# SPI6 register map
Registers from a debugger description file.
Registers are 32-bit, access not given, no defined reset value unless marked. A register's access mark holds for its fields unless they carry their own. Addresses are absolute; registers are grouped by the start of their names; lines under a group give offsets from that group; [hi:lo] are bit positions; {n}, {i} and the like mark numbered series; 'fields as' and 'values as' point back to an identical list; <NAME> marks a mode.

## SPI6
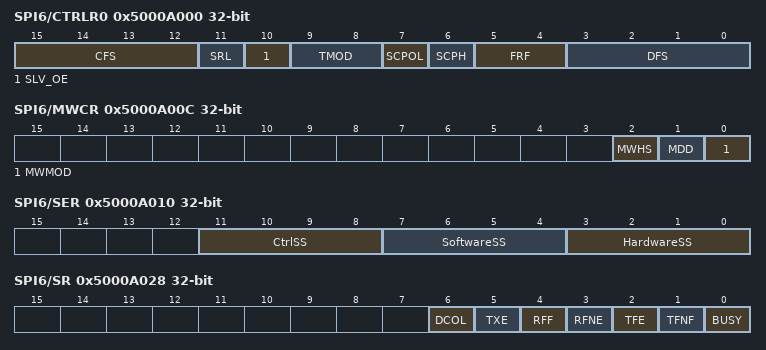
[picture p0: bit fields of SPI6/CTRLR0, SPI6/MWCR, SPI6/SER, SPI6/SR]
0x5000A000 SPI6/CTRLR0
  [15:12] CFS, [11] SRL, [10] SLV_OE, [9:8] TMOD, [7] SCPOL, [6] SCPH, [5:4] FRF, [3:0] DFS
0x5000A004 SPI6/CTRLR1
  [15:0] NDF
0x5000A008 SPI6/SSIENR
  [0] SSIENR
0x5000A00C SPI6/MWCR
  [2] MWHS, [1] MDD, [0] MWMOD
0x5000A010 SPI6/SER
  [11:8] CtrlSS, [7:4] SoftwareSS, [3:0] HardwareSS
0x5000A014 SPI6/BAUDR
  [15:0] SCKDV
0x5000A018 SPI6/TXFTLR
  [3:0] TFT
0x5000A01C SPI6/RXFTLR
  [3:0] RFT
0x5000A020 SPI6/TXFLR ro
  [3:0] TXTFL
0x5000A024 SPI6/RXFLR ro
  [3:0] RXTFL
0x5000A028 SPI6/SR ro
  [6] DCOL, [5] TXE, [4] RFF, [3] RFNE, [2] TFE, [1] TFNF, [0] BUSY
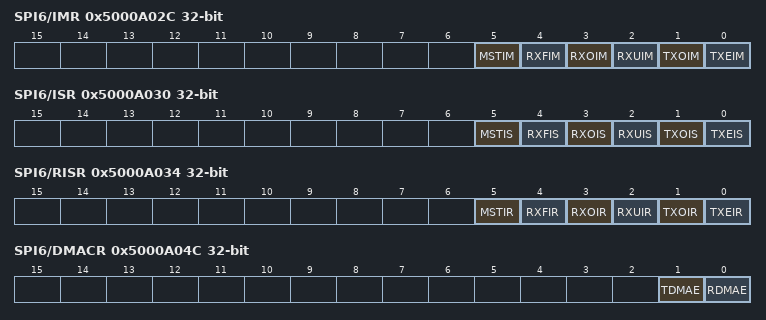
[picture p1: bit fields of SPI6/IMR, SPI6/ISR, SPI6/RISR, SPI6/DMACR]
0x5000A02C SPI6/IMR
  [5] MSTIM, [4] RXFIM, [3] RXOIM, [2] RXUIM, [1] TXOIM, [0] TXEIM
0x5000A030 SPI6/ISR ro
  [5] MSTIS, [4] RXFIS, [3] RXOIS, [2] RXUIS, [1] TXOIS, [0] TXEIS
0x5000A034 SPI6/RISR ro
  [5] MSTIR, [4] RXFIR, [3] RXOIR, [2] RXUIR, [1] TXOIR, [0] TXEIR
0x5000A038 SPI6/TXOICR ro
  [0] TXOICR
0x5000A03C SPI6/RXOICR ro
  [0] RXOICR
0x5000A040 SPI6/RXUICR ro
  [0] RXUICR
0x5000A044 SPI6/MSTICR ro
  [0] MSTICR
0x5000A048 SPI6/ICR ro
  [0] ICR
0x5000A04C SPI6/DMACR
  [1] TDMAE, [0] RDMAE
0x5000A050 SPI6/DMATDLR
  [3:0] DMATDLR
0x5000A054 SPI6/DMARDLR
  [3:0] DMARDLR
0x5000A058 SPI6/IDR ro
  [31:0] ICR
0x5000A05C SPI6/SSI_COMP_VERSION ro
0x5000A060 SPI6/DR
  [15:0] DR
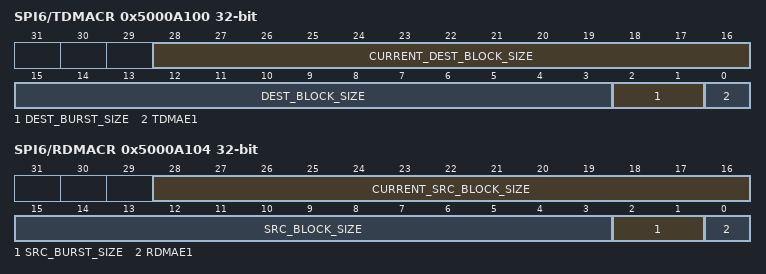
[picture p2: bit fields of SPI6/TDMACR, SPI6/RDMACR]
0x5000A100 SPI6/TDMACR
  [28:16] CURRENT_DEST_BLOCK_SIZE, [15:3] DEST_BLOCK_SIZE, [2:1] DEST_BURST_SIZE, [0] TDMAE1
0x5000A104 SPI6/RDMACR
  [28:16] CURRENT_SRC_BLOCK_SIZE, [15:3] SRC_BLOCK_SIZE, [2:1] SRC_BURST_SIZE, [0] RDMAE1
